# ESP32C3 register map
File version: 1.0
CPU: RISC-V RV32IMC single-core 1, little endian, no MPU, FPU, 3 interrupt priority bits
Registers are 32-bit, read-write, reset 0x0 unless marked. A register's access mark holds for its fields unless they carry their own. Offsets are from the block's base; [hi:lo] are bit positions; {n}, {i} and the like mark numbered series.

## RMT
Base 0x60016000
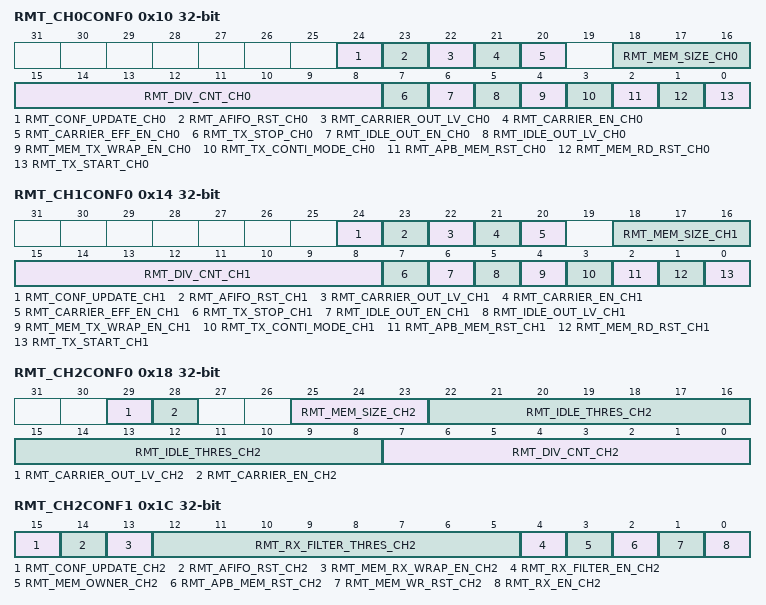
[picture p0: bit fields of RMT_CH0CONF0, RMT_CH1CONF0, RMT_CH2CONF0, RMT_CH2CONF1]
0x10 RMT_CH0CONF0 access per field
  [24] RMT_CONF_UPDATE_CH0 wo, [23] RMT_AFIFO_RST_CH0 wo, [22] RMT_CARRIER_OUT_LV_CH0 rw, [21] RMT_CARRIER_EN_CH0 rw, [20] RMT_CARRIER_EFF_EN_CH0 rw, [18:16] RMT_MEM_SIZE_CH0 rw, [15:8] RMT_DIV_CNT_CH0 rw, [7] RMT_TX_STOP_CH0 rw, [6] RMT_IDLE_OUT_EN_CH0 rw, [5] RMT_IDLE_OUT_LV_CH0 rw, [4] RMT_MEM_TX_WRAP_EN_CH0 rw, [3] RMT_TX_CONTI_MODE_CH0 rw, [2] RMT_APB_MEM_RST_CH0 wo, [1] RMT_MEM_RD_RST_CH0 wo, [0] RMT_TX_START_CH0 wo
0x14 RMT_CH1CONF0 access per field
  [24] RMT_CONF_UPDATE_CH1 wo, [23] RMT_AFIFO_RST_CH1 wo, [22] RMT_CARRIER_OUT_LV_CH1 rw, [21] RMT_CARRIER_EN_CH1 rw, [20] RMT_CARRIER_EFF_EN_CH1 rw, [18:16] RMT_MEM_SIZE_CH1 rw, [15:8] RMT_DIV_CNT_CH1 rw, [7] RMT_TX_STOP_CH1 rw, [6] RMT_IDLE_OUT_EN_CH1 rw, [5] RMT_IDLE_OUT_LV_CH1 rw, [4] RMT_MEM_TX_WRAP_EN_CH1 rw, [3] RMT_TX_CONTI_MODE_CH1 rw, [2] RMT_APB_MEM_RST_CH1 wo, [1] RMT_MEM_RD_RST_CH1 wo, [0] RMT_TX_START_CH1 wo
0x18 RMT_CH2CONF0
  [29] RMT_CARRIER_OUT_LV_CH2, [28] RMT_CARRIER_EN_CH2, [25:23] RMT_MEM_SIZE_CH2, [22:8] RMT_IDLE_THRES_CH2, [7:0] RMT_DIV_CNT_CH2
0x1C RMT_CH2CONF1 access per field
  [15] RMT_CONF_UPDATE_CH2 wo, [14] RMT_AFIFO_RST_CH2 wo, [13] RMT_MEM_RX_WRAP_EN_CH2 rw, [12:5] RMT_RX_FILTER_THRES_CH2 rw, [4] RMT_RX_FILTER_EN_CH2 rw, [3] RMT_MEM_OWNER_CH2 rw, [2] RMT_APB_MEM_RST_CH2 wo, [1] RMT_MEM_WR_RST_CH2 wo, [0] RMT_RX_EN_CH2 rw
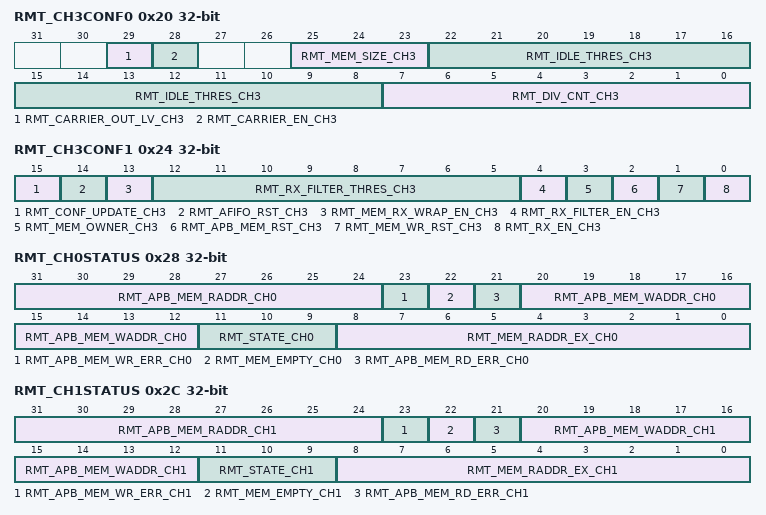
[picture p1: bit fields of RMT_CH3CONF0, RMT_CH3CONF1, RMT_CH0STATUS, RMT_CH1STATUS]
0x20 RMT_CH3CONF0
  [29] RMT_CARRIER_OUT_LV_CH3, [28] RMT_CARRIER_EN_CH3, [25:23] RMT_MEM_SIZE_CH3, [22:8] RMT_IDLE_THRES_CH3, [7:0] RMT_DIV_CNT_CH3
0x24 RMT_CH3CONF1 access per field
  [15] RMT_CONF_UPDATE_CH3 wo, [14] RMT_AFIFO_RST_CH3 wo, [13] RMT_MEM_RX_WRAP_EN_CH3 rw, [12:5] RMT_RX_FILTER_THRES_CH3 rw, [4] RMT_RX_FILTER_EN_CH3 rw, [3] RMT_MEM_OWNER_CH3 rw, [2] RMT_APB_MEM_RST_CH3 wo, [1] RMT_MEM_WR_RST_CH3 wo, [0] RMT_RX_EN_CH3 rw
0x28 RMT_CH0STATUS ro
  [31:24] RMT_APB_MEM_RADDR_CH0, [23] RMT_APB_MEM_WR_ERR_CH0, [22] RMT_MEM_EMPTY_CH0, [21] RMT_APB_MEM_RD_ERR_CH0, [20:12] RMT_APB_MEM_WADDR_CH0, [11:9] RMT_STATE_CH0, [8:0] RMT_MEM_RADDR_EX_CH0
0x2C RMT_CH1STATUS ro
  [31:24] RMT_APB_MEM_RADDR_CH1, [23] RMT_APB_MEM_WR_ERR_CH1, [22] RMT_MEM_EMPTY_CH1, [21] RMT_APB_MEM_RD_ERR_CH1, [20:12] RMT_APB_MEM_WADDR_CH1, [11:9] RMT_STATE_CH1, [8:0] RMT_MEM_RADDR_EX_CH1
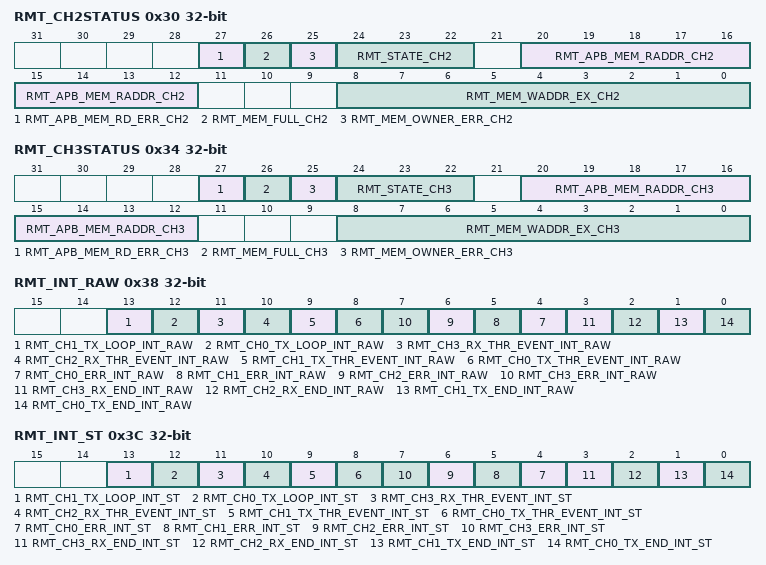
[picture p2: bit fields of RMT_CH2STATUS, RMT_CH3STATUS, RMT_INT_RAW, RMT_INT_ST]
0x30 RMT_CH2STATUS ro
  [27] RMT_APB_MEM_RD_ERR_CH2, [26] RMT_MEM_FULL_CH2, [25] RMT_MEM_OWNER_ERR_CH2, [24:22] RMT_STATE_CH2, [20:12] RMT_APB_MEM_RADDR_CH2, [8:0] RMT_MEM_WADDR_EX_CH2
0x34 RMT_CH3STATUS ro
  [27] RMT_APB_MEM_RD_ERR_CH3, [26] RMT_MEM_FULL_CH3, [25] RMT_MEM_OWNER_ERR_CH3, [24:22] RMT_STATE_CH3, [20:12] RMT_APB_MEM_RADDR_CH3, [8:0] RMT_MEM_WADDR_EX_CH3
0x38 RMT_INT_RAW
  [13] RMT_CH1_TX_LOOP_INT_RAW, [12] RMT_CH0_TX_LOOP_INT_RAW, [11] RMT_CH3_RX_THR_EVENT_INT_RAW, [10] RMT_CH2_RX_THR_EVENT_INT_RAW, [9] RMT_CH1_TX_THR_EVENT_INT_RAW, [8] RMT_CH0_TX_THR_EVENT_INT_RAW, [n+4] RMT_CH{n}_ERR_INT_RAW (n=0..3), [3] RMT_CH3_RX_END_INT_RAW, [2] RMT_CH2_RX_END_INT_RAW, [1] RMT_CH1_TX_END_INT_RAW, [0] RMT_CH0_TX_END_INT_RAW
0x3C RMT_INT_ST ro
  [13] RMT_CH1_TX_LOOP_INT_ST, [12] RMT_CH0_TX_LOOP_INT_ST, [11] RMT_CH3_RX_THR_EVENT_INT_ST, [10] RMT_CH2_RX_THR_EVENT_INT_ST, [9] RMT_CH1_TX_THR_EVENT_INT_ST, [8] RMT_CH0_TX_THR_EVENT_INT_ST, [n+4] RMT_CH{n}_ERR_INT_ST (n=0..3), [3] RMT_CH3_RX_END_INT_ST, [2] RMT_CH2_RX_END_INT_ST, [1] RMT_CH1_TX_END_INT_ST, [0] RMT_CH0_TX_END_INT_ST
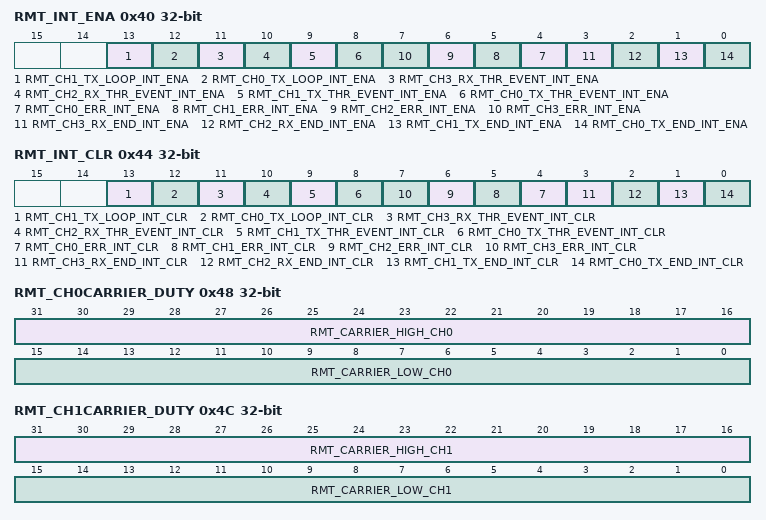
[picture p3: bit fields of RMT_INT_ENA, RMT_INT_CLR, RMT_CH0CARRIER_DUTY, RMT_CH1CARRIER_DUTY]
0x40 RMT_INT_ENA
  [13] RMT_CH1_TX_LOOP_INT_ENA, [12] RMT_CH0_TX_LOOP_INT_ENA, [11] RMT_CH3_RX_THR_EVENT_INT_ENA, [10] RMT_CH2_RX_THR_EVENT_INT_ENA, [9] RMT_CH1_TX_THR_EVENT_INT_ENA, [8] RMT_CH0_TX_THR_EVENT_INT_ENA, [n+4] RMT_CH{n}_ERR_INT_ENA (n=0..3), [3] RMT_CH3_RX_END_INT_ENA, [2] RMT_CH2_RX_END_INT_ENA, [1] RMT_CH1_TX_END_INT_ENA, [0] RMT_CH0_TX_END_INT_ENA
0x44 RMT_INT_CLR wo
  [13] RMT_CH1_TX_LOOP_INT_CLR, [12] RMT_CH0_TX_LOOP_INT_CLR, [11] RMT_CH3_RX_THR_EVENT_INT_CLR, [10] RMT_CH2_RX_THR_EVENT_INT_CLR, [9] RMT_CH1_TX_THR_EVENT_INT_CLR, [8] RMT_CH0_TX_THR_EVENT_INT_CLR, [n+4] RMT_CH{n}_ERR_INT_CLR (n=0..3), [3] RMT_CH3_RX_END_INT_CLR, [2] RMT_CH2_RX_END_INT_CLR, [1] RMT_CH1_TX_END_INT_CLR, [0] RMT_CH0_TX_END_INT_CLR
0x48 RMT_CH0CARRIER_DUTY
  [31:16] RMT_CARRIER_HIGH_CH0, [15:0] RMT_CARRIER_LOW_CH0
0x4C RMT_CH1CARRIER_DUTY
  [31:16] RMT_CARRIER_HIGH_CH1, [15:0] RMT_CARRIER_LOW_CH1
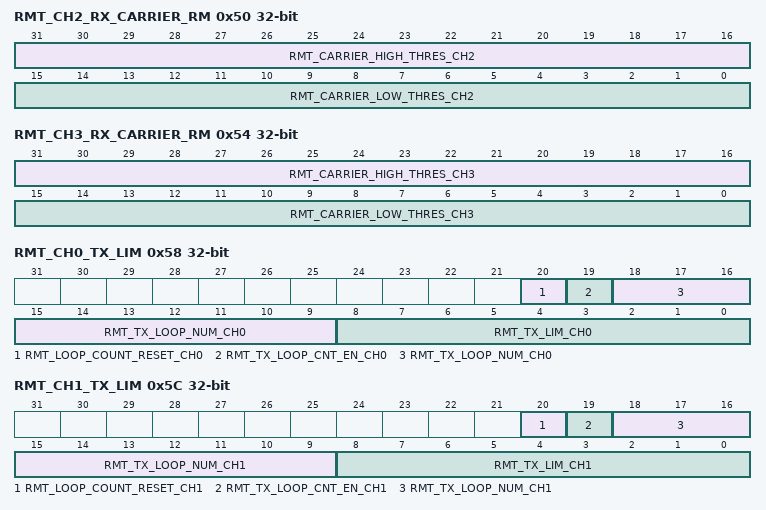
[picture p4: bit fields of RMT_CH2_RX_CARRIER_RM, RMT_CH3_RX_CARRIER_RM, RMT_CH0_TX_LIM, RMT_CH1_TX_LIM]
0x50 RMT_CH2_RX_CARRIER_RM
  [31:16] RMT_CARRIER_HIGH_THRES_CH2, [15:0] RMT_CARRIER_LOW_THRES_CH2
0x54 RMT_CH3_RX_CARRIER_RM
  [31:16] RMT_CARRIER_HIGH_THRES_CH3, [15:0] RMT_CARRIER_LOW_THRES_CH3
0x58 RMT_CH0_TX_LIM access per field
  [20] RMT_LOOP_COUNT_RESET_CH0 wo, [19] RMT_TX_LOOP_CNT_EN_CH0 rw, [18:9] RMT_TX_LOOP_NUM_CH0 rw, [8:0] RMT_TX_LIM_CH0 rw
0x5C RMT_CH1_TX_LIM access per field
  [20] RMT_LOOP_COUNT_RESET_CH1 wo, [19] RMT_TX_LOOP_CNT_EN_CH1 rw, [18:9] RMT_TX_LOOP_NUM_CH1 rw, [8:0] RMT_TX_LIM_CH1 rw
0x60 RMT_CH2_RX_LIM
  [8:0] RMT_RX_LIM_CH2
0x64 RMT_CH3_RX_LIM
  [8:0] RMT_RX_LIM_CH3
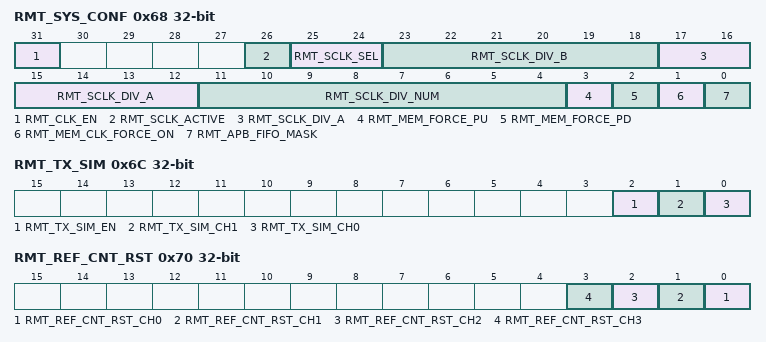
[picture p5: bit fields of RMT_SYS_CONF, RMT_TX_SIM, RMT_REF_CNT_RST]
0x68 RMT_SYS_CONF
  [31] RMT_CLK_EN, [26] RMT_SCLK_ACTIVE, [25:24] RMT_SCLK_SEL, [23:18] RMT_SCLK_DIV_B, [17:12] RMT_SCLK_DIV_A, [11:4] RMT_SCLK_DIV_NUM, [3] RMT_MEM_FORCE_PU, [2] RMT_MEM_FORCE_PD, [1] RMT_MEM_CLK_FORCE_ON, [0] RMT_APB_FIFO_MASK
0x6C RMT_TX_SIM
  [2] RMT_TX_SIM_EN, [1] RMT_TX_SIM_CH1, [0] RMT_TX_SIM_CH0
0x70 RMT_REF_CNT_RST wo
  [n] RMT_REF_CNT_RST_CH{n} (n=0..3)
0xCC RMT_DATE
  [27:0] RMT_DATE
